# YTM32B1ME1 register map
Vendor: YTMicro; File version: 1.0
CPU: CM33 r0p4, little endian, MPU, FPU, 2 interrupt priority bits
Registers are 32-bit, read-write, reset 0x0 unless marked. A register's access mark holds for its fields unless they carry their own. Offsets are from the block's base; [hi:lo] are bit positions; {n}, {i} and the like mark numbered series.

## INTM — Interrupt Monitor Unit
Base 0x401C4000; register names take the prefix INTM_
0x00 GCTRL
  [0] GEN — The field is used to enable or disable all monitors
    0=interrupt monitor is disabled; 1=interrupt monitor is enabled
0x04 GINTACK
  [9:0] SRC — This field is used to specify the interrupt request number to service the INTM INT. Subsequently, need to write it again when the overflow interrupt under monitor is serviced correctly to continue INTM function.
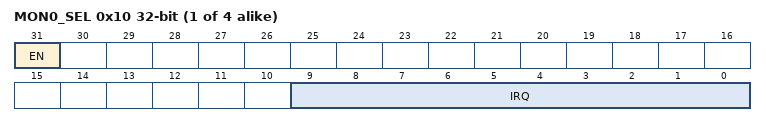
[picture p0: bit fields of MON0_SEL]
{0x10+0x10*i} MON{i}_SEL (i=0..3)
  [31] EN — This field is used to enable or disable this monitor
  [9:0] IRQ — This field is used to select the monitored interrupt source
{0x14+0x10*i} MON{i}_THD reset 0xFFFFFF (i=0..3)
  [23:0] THRESHOLD — This field is used to configure the maximum number of INTM clock cycles allowed for the monitored interrupt request
{0x18+0x10*i} MON{i}_TMR (i=0..3)
  [23:0] CNT — This field is used to count the number of INTM clock cycles, up to 24 bits of resolution, write any value to reset the CNT.
{0x1C+0x10*i} MON{i}_STS ro (i=0..3)
  [0] OF rw — This field indicates whether MONn_TMR value has exceeded the MONn_THRESHOLD value.

## WDG0 — Watchdog module
Base 0x401A8000; register names take the prefix WDG0_
0x00 SVCR wo — Watchdog Service Code Register
  [15:0] SVCODE — It can be used to service the watchdog or to clear the soft lock bit. Writing 0xB631 followed by 0xC278 will clear the soft lock bit, writing 0xA518 followed by 0xD826 to service the watchdog.
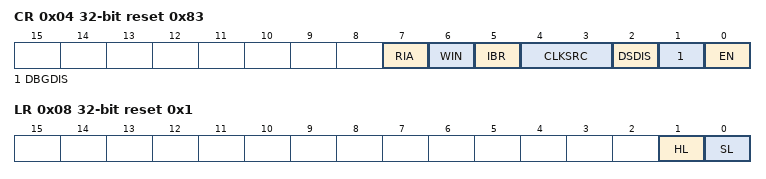
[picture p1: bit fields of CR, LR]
0x04 CR reset 0x83 — Watchdog Control Register
  [7] RIA — Enable reset for invalid APB access.
    0=Generate bus error on invalid APB access; 1=Generate bus error and system reset on invalid APB access
  [6] WIN — Enable window mode.
    0=Disable window mode, watchdog service can be done at any time; 1=Enable window mode, watchdog service is can only be done when timer value is less than the value of WIN register
  [5] IBR — Enable interrupt before reset function
    0=Disable interrupt before reset; 1=Enable interrupt before reset, when watchdog time-out, generate an interrupt first and when next time-out happens, generate reset
  [4:3] CLKSRC
    0=LPO Clock; 1=SIRC Clock; 2=Functional Clock from IPC; 3=WDG Bus Clock
  [2] DSDIS — Enable or disable watchdog in deepsleep mode
    0=Enable watchdog in deepsleep mode; 1=Disable watchdog in deepsleep mode
  [1] DBGDIS — Enable or disable watchdog in debug mode.
    0=Enable watchdog in debug mode; 1=Disable watchdog in debug mode
  [0] EN — Enable watchdog module.
    0=Disable watchdog module; 1=Enable watchdog module
0x08 LR reset 0x1 — Watchdog Lock Register
  [1] HL — Hard lock, when this bit set, the CR, WIN, TOVR are read-only. once set, the bit can only be clear by reset.
  [0] SL — Soft lock, when this bit set, the CR, WIN, TOVR are read-only. this bit can be clear by writing a valid sequence to SVCR register.
0x0C TOVR reset 0xC00 — Watchdog Timer Overflow Value
  [31:0] TO — A 32bit down counter uses this value to start count. Writing value should be greater than 0x100. Otherwise 0x100 is written to this register.
0x10 WVR
  [31:0] WIN — When CR[WIN] is set, the window mode is enabled, the service sequence can only be written when the timer value is less than the value of this register.
0x14 CNTCVR ro — Watchdog Counter Current Value Register
  [31:0] CVAL
0x18 INTF — Watchdog Interrupt Flag register
  [0] IF — Watchdog interrupt flag. Write 1 to this field to clear the flag and interrupt.
    0=No watchdog interrupt is pending; 1=Watchdog timer time-out interrupt is pending

## EWDG0 — External Watchdog
Base 0x401AC000; register names take the prefix EWDG0_
0x00 SERV — The SERV register is write only and reads of this register return zero.
  [7:0] SERVICE — The EWDG refresh mechanism requires the CPU to write two values to the SERV register: a first data byte of 0xA8, followed by a second data byte of 0x6C. The EWDG refresh is invalid if either of the following conditions is true. The first or second data byte is not written correctly. The second data byte is not written within 63 peripheral bus cycles of the first data byte.
0x04 CMPL — The CMPL register will be reset to zero after reset.
  [15:0] COMPAREL — Low value of EWDG counter compare.
0x08 CMPH reset 0xFFFF — The CMPH register will be reset to 0xFFFF after reset.
  [15:0] COMPAREH — High value of EWDG counter compare. The max value of COMPAREH is 0xFFFE because the EWDG will never expires if it is 0xFFFF.
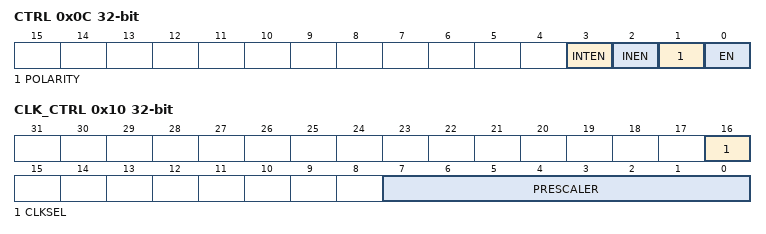
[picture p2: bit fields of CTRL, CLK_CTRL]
0x0C CTRL — This register contains the control bits for EWDG.
  [3] INTEN — This bit when set and EWDG_OUT_b is asserted, an interrupt request is generated. To de-assert interrupt request, user should clear this bit by writing 0.
    0=No EWDG interrupt occurs; 1=EWDG interrupt occurs
  [2] INEN — Enable EWDG_IN pin.
    0=Disable EWDG_IN pin; 1=Enable EWDG_IN pin
  [1] POLARITY — Control the polarity of EWDG_IN pin
    0=input EWDG_IN pin directly; 1=input inverted EWDG_IN pin
  [0] EN — When this bit is set, EWDG module is enabled and the EWDG counter is reset to zero and EWDG_OUT_b is deasserted.
    0=Disable EWDG module; 1=Enable EWDG module
0x10 CLK_CTRL — This register contains the bits to control the clock source for running EWDG. Write the required prescaler value before enabling the EWDG.
  [16] CLKSEL — Select EWDG functional clock source
    0=SIRC; 1=LPO_CLK
  [7:0] PRESCALER
